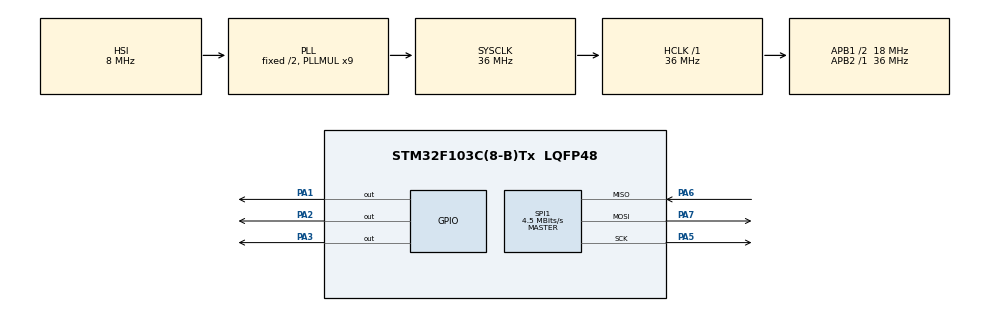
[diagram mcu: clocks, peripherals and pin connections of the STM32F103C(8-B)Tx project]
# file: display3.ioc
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Dma.Request0=SPI1_TX
Dma.SPI1_TX.0.Direction=DMA_MEMORY_TO_PERIPH
Dma.SPI1_TX.0.Instance=DMA1_Channel3
Dma.SPI1_TX.0.MemDataAlignment=DMA_MDATAALIGN_BYTE
Dma.SPI1_TX.0.MemInc=DMA_MINC_ENABLE
Dma.SPI1_TX.0.Mode=DMA_NORMAL
Dma.SPI1_TX.0.PeriphDataAlignment=DMA_PDATAALIGN_BYTE
Dma.SPI1_TX.0.PeriphInc=DMA_PINC_DISABLE
Dma.SPI1_TX.0.Priority=DMA_PRIORITY_LOW
Mcu.Family=STM32F1
Mcu.Name=STM32F103C(8-B)Tx
Mcu.Package=LQFP48
NVIC.DMA1_Channel3_IRQn=true\:0\:0\:false\:false\:true\:false\:true\:true
NVIC.PriorityGroup=NVIC_PRIORITYGROUP_4
NVIC.SPI1_IRQn=true\:0\:0\:false\:false\:true\:true\:true\:true
PA1.Signal=GPIO_Output
PA13.Mode=Serial_Wire
PA13.Signal=SYS_JTMS-SWDIO
PA14.Mode=Serial_Wire
PA14.Signal=SYS_JTCK-SWCLK
PA2.Signal=GPIO_Output
PA3.Signal=GPIO_Output
PA5.Mode=Full_Duplex_Master
PA5.Signal=SPI1_SCK
PA6.Mode=Full_Duplex_Master
PA6.Signal=SPI1_MISO
PA7.Mode=Full_Duplex_Master
PA7.Signal=SPI1_MOSI
ProjectManager.HeapSize=0x3000
ProjectManager.StackSize=0x1000
ProjectManager.TargetToolchain=STM32CubeIDE
RCC.AHBFreq_Value=36000000
RCC.APB1CLKDivider=RCC_HCLK_DIV2
RCC.APB1Freq_Value=18000000
RCC.APB1TimFreq_Value=36000000
RCC.APB2Freq_Value=36000000
RCC.APB2TimFreq_Value=36000000
RCC.HCLKFreq_Value=36000000
RCC.PLLMUL=RCC_PLL_MUL9
RCC.SYSCLKFreq_VALUE=36000000
RCC.SYSCLKSource=RCC_SYSCLKSOURCE_PLLCLK
RCC.USBFreq_Value=36000000
SPI1.BaudRatePrescaler=SPI_BAUDRATEPRESCALER_8
SPI1.CLKPhase=SPI_PHASE_2EDGE
SPI1.CLKPolarity=SPI_POLARITY_HIGH
SPI1.CalculateBaudRate=4.5 MBits/s
SPI1.Direction=SPI_DIRECTION_2LINES
SPI1.Mode=SPI_MODE_MASTER
SPI1.VirtualType=VM_MASTER
board=custom

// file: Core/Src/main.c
/* USER CODE BEGIN Header */
/*
 *
 https://github.com/Floyd-Fish/ST7789-STM32/
 Display 240x320

 */
/**
  ******************************************************************************
  * @file           : main.c
  * @brief          : Main program body
  ******************************************************************************
  * @attention
  *
  * Copyright (c) 2025 STMicroelectronics.
  * All rights reserved.
  *
  * This software is licensed under terms that can be found in the LICENSE file
  * in the root directory of this software component.
  * If no LICENSE file comes with this software, it is provided AS-IS.
  *
  ******************************************************************************
  */
/* USER CODE END Header */
#include "main.h"

/* USER CODE BEGIN Includes */
#include <stdbool.h>
#include <stdlib.h>

#include "st7789.h"
#include "fonts.h"
/* USER CODE END Includes */

SPI_HandleTypeDef hspi1;
DMA_HandleTypeDef hdma_spi1_tx;

void SystemClock_Config(void);
static void MX_GPIO_Init(void);
static void MX_DMA_Init(void);
static void MX_SPI1_Init(void);

int main(void)
{

  /* MCU Configuration--------------------------------------------------------*/

  /* Reset of all peripherals, Initializes the Flash interface and the Systick. */
  HAL_Init();

  /* Configure the system clock */
  SystemClock_Config();

  /* Initialize all configured peripherals */
  MX_GPIO_Init();
  MX_DMA_Init();
  MX_SPI1_Init();
  /* USER CODE BEGIN 2 */

  ST7789_Init();

  HAL_GPIO_WritePin(GPIOA, GPIO_PIN_3, GPIO_PIN_SET);
  //ST7789_Fill_Color(RED);
  /* USER CODE END 2 */

  /* Infinite loop */
  /* USER CODE BEGIN WHILE */
  while (1)
  {
	  ST7789_Test();
    /* USER CODE END WHILE */

  }
}

void SystemClock_Config(void)
{
  RCC_OscInitTypeDef RCC_OscInitStruct = {0};
  RCC_ClkInitTypeDef RCC_ClkInitStruct = {0};

  /** Initializes the RCC Oscillators according to the specified parameters
  * in the RCC_OscInitTypeDef structure.
  */
  RCC_OscInitStruct.OscillatorType = RCC_OSCILLATORTYPE_HSI;
  RCC_OscInitStruct.HSIState = RCC_HSI_ON;
  RCC_OscInitStruct.HSICalibrationValue = RCC_HSICALIBRATION_DEFAULT;
  RCC_OscInitStruct.PLL.PLLState = RCC_PLL_ON;
  RCC_OscInitStruct.PLL.PLLSource = RCC_PLLSOURCE_HSI_DIV2;
  RCC_OscInitStruct.PLL.PLLMUL = RCC_PLL_MUL9;
  if (HAL_RCC_OscConfig(&RCC_OscInitStruct) != HAL_OK)
  {
    Error_Handler();
  }

  /** Initializes the CPU, AHB and APB buses clocks
  */
  RCC_ClkInitStruct.ClockType = RCC_CLOCKTYPE_HCLK|RCC_CLOCKTYPE_SYSCLK
                              |RCC_CLOCKTYPE_PCLK1|RCC_CLOCKTYPE_PCLK2;
  RCC_ClkInitStruct.SYSCLKSource = RCC_SYSCLKSOURCE_PLLCLK;
  RCC_ClkInitStruct.AHBCLKDivider = RCC_SYSCLK_DIV1;
  RCC_ClkInitStruct.APB1CLKDivider = RCC_HCLK_DIV2;
  RCC_ClkInitStruct.APB2CLKDivider = RCC_HCLK_DIV1;

  if (HAL_RCC_ClockConfig(&RCC_ClkInitStruct, FLASH_LATENCY_1) != HAL_OK)
  {
    Error_Handler();
  }
}

static void MX_SPI1_Init(void)
{

  /* SPI1 parameter configuration*/
  hspi1.Instance = SPI1;
  hspi1.Init.Mode = SPI_MODE_MASTER;
  hspi1.Init.Direction = SPI_DIRECTION_2LINES;
  hspi1.Init.DataSize = SPI_DATASIZE_8BIT;
  hspi1.Init.CLKPolarity = SPI_POLARITY_HIGH;
  hspi1.Init.CLKPhase = SPI_PHASE_2EDGE;
  hspi1.Init.NSS = SPI_NSS_SOFT;
  hspi1.Init.BaudRatePrescaler = SPI_BAUDRATEPRESCALER_8;
  hspi1.Init.FirstBit = SPI_FIRSTBIT_MSB;
  hspi1.Init.TIMode = SPI_TIMODE_DISABLE;
  hspi1.Init.CRCCalculation = SPI_CRCCALCULATION_DISABLE;
  hspi1.Init.CRCPolynomial = 10;
  if (HAL_SPI_Init(&hspi1) != HAL_OK)
  {
    Error_Handler();
  }

}

static void MX_DMA_Init(void)
{

  /* DMA controller clock enable */
  __HAL_RCC_DMA1_CLK_ENABLE();

  /* DMA interrupt init */
  /* DMA1_Channel3_IRQn interrupt configuration */
  HAL_NVIC_SetPriority(DMA1_Channel3_IRQn, 0, 0);
  HAL_NVIC_EnableIRQ(DMA1_Channel3_IRQn);

}

static void MX_GPIO_Init(void)
{
  GPIO_InitTypeDef GPIO_InitStruct = {0};

  /* GPIO Ports Clock Enable */
  __HAL_RCC_GPIOA_CLK_ENABLE();

  /*Configure GPIO pin Output Level */
  HAL_GPIO_WritePin(GPIOA, GPIO_PIN_1|GPIO_PIN_2|GPIO_PIN_3, GPIO_PIN_RESET);

  /*Configure GPIO pins : PA1 PA2 PA3 */
  GPIO_InitStruct.Pin = GPIO_PIN_1|GPIO_PIN_2|GPIO_PIN_3;
  GPIO_InitStruct.Mode = GPIO_MODE_OUTPUT_PP;
  GPIO_InitStruct.Pull = GPIO_NOPULL;
  GPIO_InitStruct.Speed = GPIO_SPEED_FREQ_LOW;
  HAL_GPIO_Init(GPIOA, &GPIO_InitStruct);

}

void Error_Handler(void)
{
  __disable_irq();
  while (1)
  {
  }
}
